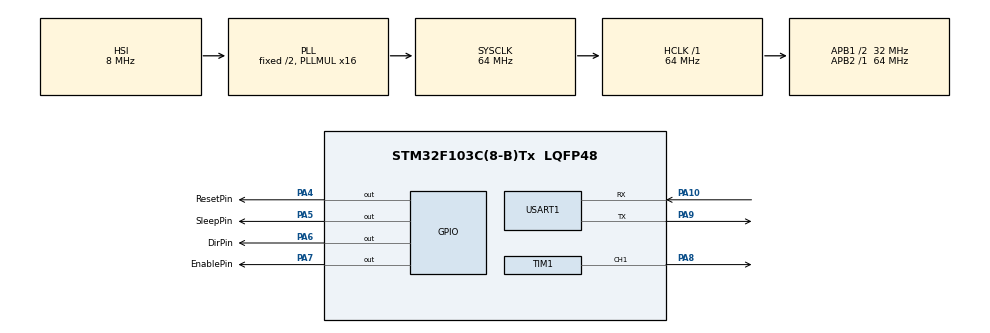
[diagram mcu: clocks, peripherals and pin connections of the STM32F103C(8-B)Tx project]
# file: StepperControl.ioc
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Mcu.Family=STM32F1
Mcu.Name=STM32F103C(8-B)Tx
Mcu.Package=LQFP48
NVIC.PriorityGroup=NVIC_PRIORITYGROUP_4
NVIC.USART1_IRQn=true\:0\:0\:false\:false\:true\:true\:true\:true
PA10.Mode=Asynchronous
PA10.Signal=USART1_RX
PA4.GPIO_Label=ResetPin
PA4.GPIO_Speed=GPIO_SPEED_FREQ_HIGH
PA4.PinState=GPIO_PIN_SET
PA4.Signal=GPIO_Output
PA5.GPIO_Label=SleepPin
PA5.GPIO_Speed=GPIO_SPEED_FREQ_HIGH
PA5.PinState=GPIO_PIN_SET
PA5.Signal=GPIO_Output
PA6.GPIO_Label=DirPin
PA6.PinState=GPIO_PIN_RESET
PA6.Signal=GPIO_Output
PA7.GPIO_Label=EnablePin
PA7.Signal=GPIO_Output
PA8.Signal=S_TIM1_CH1
PA9.Mode=Asynchronous
PA9.Signal=USART1_TX
ProjectManager.HeapSize=0x200
ProjectManager.StackSize=0x400
ProjectManager.TargetToolchain=STM32CubeIDE
RCC.AHBFreq_Value=64000000
RCC.APB1CLKDivider=RCC_HCLK_DIV2
RCC.APB1Freq_Value=32000000
RCC.APB1TimFreq_Value=64000000
RCC.APB2Freq_Value=64000000
RCC.APB2TimFreq_Value=64000000
RCC.HCLKFreq_Value=64000000
RCC.PLLMUL=RCC_PLL_MUL16
RCC.SYSCLKFreq_VALUE=64000000
RCC.SYSCLKSource=RCC_SYSCLKSOURCE_PLLCLK
RCC.USBFreq_Value=64000000
SH.S_TIM1_CH1.0=TIM1_CH1,PWM Generation1 CH1
TIM1.Channel-PWM\ Generation1\ CH1=TIM_CHANNEL_1
TIM1.Period=999
TIM1.Prescaler=63
TIM1.Pulse-PWM\ Generation1\ CH1=500
USART1.VirtualMode=VM_ASYNC
VP_SYS_VS_ND.Mode=No_Debug
VP_TIM1_VS_ClockSourceINT.Mode=Internal
board=custom

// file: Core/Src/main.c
/* USER CODE BEGIN Header */
/**
  ******************************************************************************
  * @file           : main.c
  * @brief          : Main program body
  ******************************************************************************
  * @attention
  *
  * Copyright (c) 2025 STMicroelectronics.
  * All rights reserved.
  *
  * This software is licensed under terms that can be found in the LICENSE file
  * in the root directory of this software component.
  * If no LICENSE file comes with this software, it is provided AS-IS.
  *
  ******************************************************************************
  */
/* USER CODE END Header */
#include "main.h"
#include "tim.h"
#include "usart.h"
#include "gpio.h"

void SystemClock_Config(void);

/* USER CODE BEGIN 0 */
void setStepsFreq(uint32_t arr) {
    __HAL_TIM_DISABLE(&htim1);                         // Ferma il timer
    __HAL_TIM_SET_AUTORELOAD(&htim1, arr);             // Imposta ARR
    __HAL_TIM_SET_COMPARE(&htim1, TIM_CHANNEL_1, arr/2); // Imposta duty cycle
    __HAL_TIM_ENABLE(&htim1);                          // Riavvia il timer
}
/* USER CODE END 0 */

int main(void)
{

  /* USER CODE BEGIN 1 */
	  /*HAL_GPIO_WritePin(GPIOA,  ResetPin_Pin, GPIO_PIN_RESET);
	  HAL_GPIO_WritePin(GPIOA,  SleepPin_Pin, GPIO_PIN_RESET);
	  HAL_Delay(2000);
	  HAL_GPIO_WritePin(GPIOA,  ResetPin_Pin, GPIO_PIN_SET);
	  HAL_GPIO_WritePin(GPIOA,  SleepPin_Pin, GPIO_PIN_SET);*/
  /* USER CODE END 1 */

  /* MCU Configuration--------------------------------------------------------*/

  /* Reset of all peripherals, Initializes the Flash interface and the Systick. */
  HAL_Init();

  /* Configure the system clock */
  SystemClock_Config();

  /* Initialize all configured peripherals */
  MX_GPIO_Init();
  MX_USART1_UART_Init();
  MX_TIM1_Init();

  HAL_TIM_PWM_Start(&htim1, TIM1);
  /* USER CODE BEGIN 2 */

  /*void delay_us(uint32_t us) {
      uint32_t start = DWT->CYCCNT;
      uint32_t ticks = us * (HAL_RCC_GetHCLKFreq() / 1000000);
      while ((DWT->CYCCNT - start) < ticks);
  }

  void Move(uint32_t Delay_us) {
      HAL_GPIO_WritePin(GPIOA, StepPin_Pin, GPIO_PIN_SET);
      delay_us(Delay_us);
      HAL_GPIO_WritePin(GPIOA, StepPin_Pin, GPIO_PIN_RESET);
      delay_us(Delay_us);
  }*/
  // usa htim1 come esempio

  /* USER CODE END 2 */

  /* Infinite loop */
  while (1)
  {
	  // motore avanti
	  for (uint32_t p = 3000; p > 1000; p-=50) {
	      setStepsFreq(p);
	      HAL_Delay(50);
	  }
	  HAL_Delay(3000);
	  for (uint32_t p = 1000; p < 3000; p+=50) {
	  	      setStepsFreq(p);
	  	      HAL_Delay(50);
	  	  }

  }
}

void SystemClock_Config(void)
{
  RCC_OscInitTypeDef RCC_OscInitStruct = {0};
  RCC_ClkInitTypeDef RCC_ClkInitStruct = {0};

  /** Initializes the RCC Oscillators according to the specified parameters
  * in the RCC_OscInitTypeDef structure.
  */
  RCC_OscInitStruct.OscillatorType = RCC_OSCILLATORTYPE_HSI;
  RCC_OscInitStruct.HSIState = RCC_HSI_ON;
  RCC_OscInitStruct.HSICalibrationValue = RCC_HSICALIBRATION_DEFAULT;
  RCC_OscInitStruct.PLL.PLLState = RCC_PLL_ON;
  RCC_OscInitStruct.PLL.PLLSource = RCC_PLLSOURCE_HSI_DIV2;
  RCC_OscInitStruct.PLL.PLLMUL = RCC_PLL_MUL16;
  if (HAL_RCC_OscConfig(&RCC_OscInitStruct) != HAL_OK)
  {
    Error_Handler();
  }

  /** Initializes the CPU, AHB and APB buses clocks
  */
  RCC_ClkInitStruct.ClockType = RCC_CLOCKTYPE_HCLK|RCC_CLOCKTYPE_SYSCLK
                              |RCC_CLOCKTYPE_PCLK1|RCC_CLOCKTYPE_PCLK2;
  RCC_ClkInitStruct.SYSCLKSource = RCC_SYSCLKSOURCE_PLLCLK;
  RCC_ClkInitStruct.AHBCLKDivider = RCC_SYSCLK_DIV1;
  RCC_ClkInitStruct.APB1CLKDivider = RCC_HCLK_DIV2;
  RCC_ClkInitStruct.APB2CLKDivider = RCC_HCLK_DIV1;

  if (HAL_RCC_ClockConfig(&RCC_ClkInitStruct, FLASH_LATENCY_2) != HAL_OK)
  {
    Error_Handler();
  }
}

void Error_Handler(void)
{
  __disable_irq();
  while (1)
  {
  }
}
